# SN32F240 register map
Vendor: SONiX Technology Co., Ltd.; Series: SN32F200; File version: 2.0
CPU: CM0 r0p0, little endian, no MPU, no FPU, 2 interrupt priority bits
Registers are 32-bit, read-write, reset 0x0 unless marked. A register's access mark holds for its fields unless they carry their own. Offsets are from the block's base; [hi:lo] are bit positions; {n}, {i} and the like mark numbered series.

## SN_FLASH — FLASH Memory Control Registers
Base 0x40062000
0x00 LPCTRL — Offset:0x00 Flash Low Power Control Register
  [1:0] LPMODE — Flash Low Power mode enable bit
    0=Disable; 2=Enable Slow mode power saving when HCLK=ILRC=32KHz
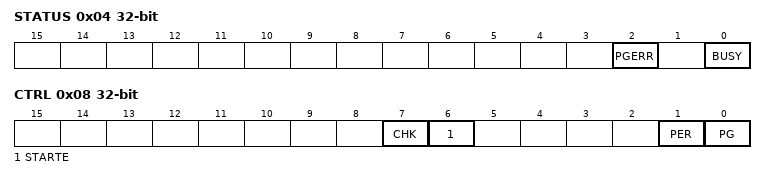
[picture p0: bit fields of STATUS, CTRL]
0x04 STATUS — Offset:0x04 Flash Status Register
  [2] PGERR — Programming error flag
    0=No error; 1=Error (The address to be programmed is illegal or contains a value different from 0xFFFFFFFF)
  [0] BUSY ro — Busy flag
    0=Idle (FMC is idle); 1=Busy (Flash operation is in process)
0x08 CTRL — Offset:0x08 Flash Control Register
  [7] CHK — Checksum calculation choosen
    0=Disable; 1=Enable (Trigger checksum calculation)
  [6] STARTE — Start erase enable bit
    0=Erase operation is stopped/finished; 1=Start erase operation
  [1] PER — Page erase enable bit
    0=Disable page erase operation; 1=Enable page erase operation
  [0] PG — Flash program enable bit
    0=Disable Flash program operation; 1=Enable Flash program operation
0x0C DATA — Offset:0x0C Flash Data Register
0x10 ADDR — Offset:0x10 Flash Address Register
0x14 CHKSUM ro (reset mask 0xFFFF) — Offset:0x14 Flash Checksum Register

## SN_LCD — 4 x 32 LCD Driver
Base 0x40034000
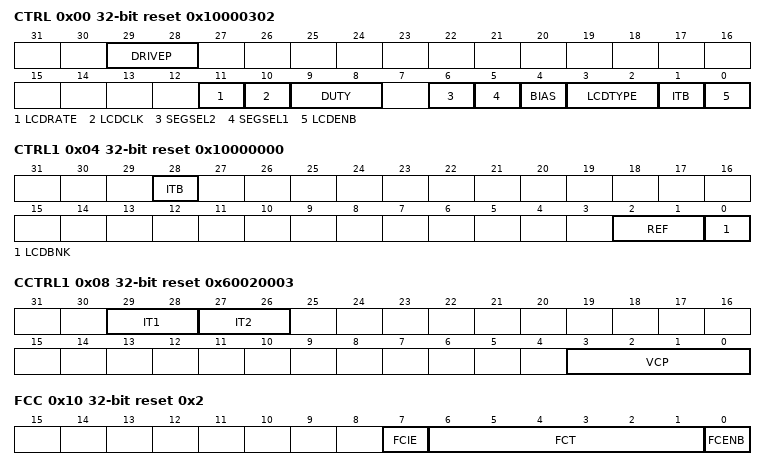
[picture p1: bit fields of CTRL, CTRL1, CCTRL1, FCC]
0x00 CTRL reset 0x10000302 — Offset:0x00 LCD Control register
  [29:28] DRIVEP — LCD panel driving ability
    0=Strong (Large panel); 1=Medium panel; 3=Low (Smaller panel)
  [11] LCDRATE — LCD clock rate
    0=LCD clock rate=LCD clock source/64; 1=LCD clock rate=LCD clock source/128
  [10] LCDCLK — LCD clock source selection
    0=ILRC (ILRC is LCD clock source); 1=ELS XTAL (ELS Xtal is LCD clock source)
  [9:8] DUTY — Duty selection
    1=1/2 duty; 2=1/3 duty; 3=1/4 duty
  [6] SEGSEL2 — SEG24~31 enable bit
    0=Disable (SEG24~31 are GPIO pins); 1=Enable (SEG24~31 are LCD segment pins)
  [5] SEGSEL1 — SEG12~23 enable bit
    0=Disable (SEG12~23 are GPIO pins); 1=Enable (SEG12~23 are LCD segment pins)
  [4] BIAS — LCD bias selection
    0=1/3 bias; 1=1/2 bias
  [3:2] LCDTYPE — LCD type control bit
    0=R (R-type LCD); 1=4C (4C-type LCD); 2=1C (1C-type LCD)
  [1] ITB — Internal testing bit
  [0] LCDENB — LCD driver enable bit
    0=Disable LCD; 1=Enable LCD
0x04 CTRL1 reset 0x10000000 — Offset:0x04 LCD Control register 1
  [28] ITB — Internal testing bit
    0=Only value 0 is allowed
  [2:1] REF — Resistance selection for LCD Bias Voltage-division
    0=400K; 1=200K; 2=100K; 3=35K
  [0] LCDBNK — LCD blank control bit
    0=Normal display; 1=Blank (All LCD dots Off)
0x08 CCTRL1 reset 0x60020003 (reset mask 0xEC3FFC0F) — Offset:0x08 LCD C-Type Control register 1
  [29:28] IT1 — Internal testing bits
  [27:26] IT2 — Internal testing bits
  [3:0] VCP — C-Type VLCD output voltage
    0=VLCD=2.70V; 1=VLCD=2.80V; 2=VLCD=2.90V; 3=VLCD=3.00V; 4=1C: VLCD=3.10V, 4C: VLCD=3.06V; 5=1C: VLCD=3.20V, 4C: VLCD=3.14V; 6=1C: VLCD=3.30V, 4C: VLCD=3.20V; 7=1C: VLCD=3.40V, 4C: VLCD=3.30V; 8=1C: N/A, 4C: VLCD=3.40V; 9=1C: N/A, 4C: VLCD=3.60V; 10=1C: N/A, 4C: VLCD=3.80V; 11=1C: N/A, 4C: VLCD=4.00V; 12=1C: N/A, 4C: VLCD=4.20V; 13=1C: N/A, 4C: VLCD=4.40V; 14=1C: N/A, 4C: VLCD=4.70V; 15=1C: N/A, 4C: VLCD=5.00V
0x0C CCTRL2 reset 0x2 — Offset:0x0C LCD C-Type Control register 2
  [3:1] IT — Internal testing bits
0x10 FCC reset 0x2 — Offset:0x10 LCD Frame Counter Control register
  [7] FCIE — LCD frame interrupt enable bit
    0=Disable LCD frame interrupt; 1=Enable LCD frame interrupt
  [6:1] FCT — LCD frame counter threshold value
  [0] FCENB — LCD frame counter enable bit
    0=Disable LCD frame counter; 1=Enable LCD frame counter
0x14 RIS — Offset:0x14 LCD Raw Interrupt Status register
  [0] FCIF — LCD frame interrupt flag
    0=No interrupt; 1=FC interrupt requirements met
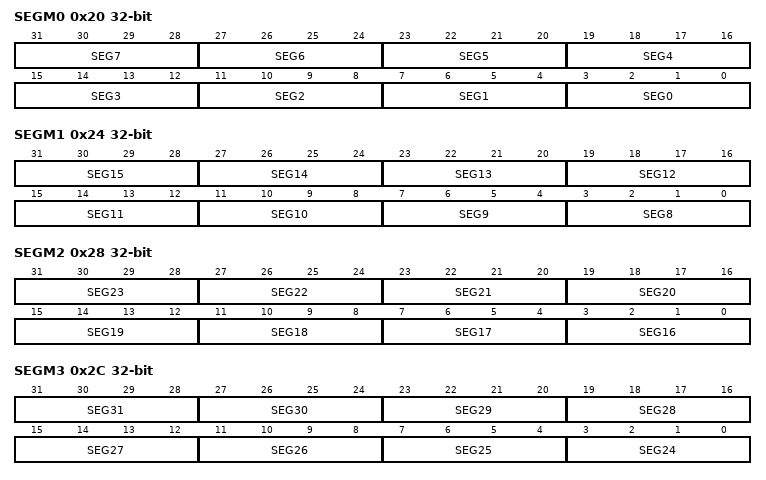
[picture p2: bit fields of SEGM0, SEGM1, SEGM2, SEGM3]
0x20 SEGM0 — Offset:0x20 LCD SEG Memory register 0
  [4n+3:4n] SEG{n} (n=0..7) — SEG{n} data for COM0~COM3
0x24 SEGM1 — Offset:0x24 LCD SEG Memory register 1
  [4n-29:4n-32] SEG{n} (n=8..15) — SEG{n} data for COM0~COM3
0x28 SEGM2 — Offset:0x28 LCD SEG Memory register 2
  [4n-61:4n-64] SEG{n} (n=16..23) — SEG{n} data for COM0~COM3
0x2C SEGM3 — Offset:0x2C LCD SEG Memory register 3
  [4n-93:4n-96] SEG{n} (n=24..31) — SEG{n} data for COM0~COM3

## SN_UC — UC Registers
Base 0x1FFF2C08
0x00 L4BYTE ro — Offset:0x00 UC Low 4 Byte Register
0x04 H4BYTE ro — Offset:0x04 UC High 4 Byte Register
